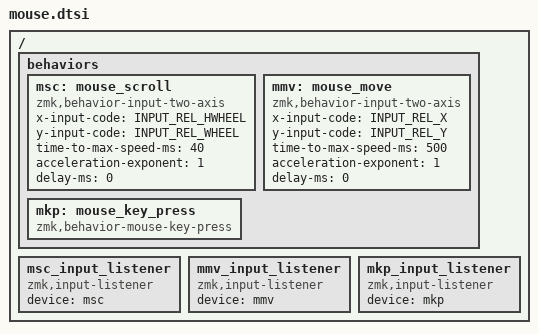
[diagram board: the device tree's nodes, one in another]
#include <dt-bindings/zmk/mouse.h>
#include <zephyr/dt-bindings/input/input-event-codes.h>

/ {
    behaviors {
        /omit-if-no-ref/ msc: mouse_scroll {
            compatible = "zmk,behavior-input-two-axis";
            #binding-cells = <1>;
            x-input-code = <INPUT_REL_HWHEEL>;
            y-input-code = <INPUT_REL_WHEEL>;
            time-to-max-speed-ms = <300>;
            acceleration-exponent = <0>;
        };
    };

    msc_input_listener: msc_input_listener {
        compatible = "zmk,input-listener";
        device = <&msc>;
    };
};

/ {
    behaviors {
        /omit-if-no-ref/ mmv: mouse_move {
            compatible = "zmk,behavior-input-two-axis";
            #binding-cells = <1>;
            x-input-code = <INPUT_REL_X>;
            y-input-code = <INPUT_REL_Y>;
            time-to-max-speed-ms = <300>;
            acceleration-exponent = <1>;
        };
    };

    mmv_input_listener: mmv_input_listener {
        compatible = "zmk,input-listener";
        device = <&mmv>;
    };
};

/ {
    behaviors {
        /omit-if-no-ref/ mkp: mouse_key_press {
            compatible = "zmk,behavior-mouse-key-press";
            #binding-cells = <1>;
        };
    };

    mkp_input_listener: mkp_input_listener {
        compatible = "zmk,input-listener";
        device = <&mkp>;
    };
};

//----------------------------------------------//

#define ZMK_MOUSE_DEFAULT_MOVE_VAL 1500  // 600
#define ZMK_MOUSE_DEFAULT_SCRL_VAL 20    // 10

&mmv {
  acceleration-exponent = <1>;      // 1
  time-to-max-speed-ms = <500>;    // 40
  delay-ms = <0>;                   // 0
};

&msc {
  acceleration-exponent = <1>;      // 0
  time-to-max-speed-ms = <40>;      // 500
  delay-ms = <0>;                   // 10
};

#define U_MS_U &mmv MOVE_UP
#define U_MS_D &mmv MOVE_DOWN
#define U_MS_L &mmv MOVE_LEFT
#define U_MS_R &mmv MOVE_RIGHT
#define U_WH_U &msc SCRL_UP
#define U_WH_D &msc SCRL_DOWN
#define U_WH_L &msc SCRL_LEFT
#define U_WH_R &msc SCRL_RIGHT
